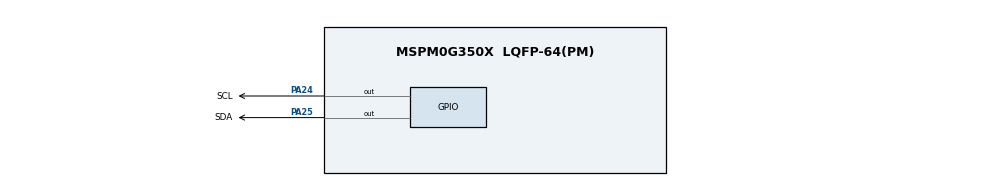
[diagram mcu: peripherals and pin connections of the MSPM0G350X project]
/**
 * These arguments were used when this file was generated. They will be automatically applied on subsequent loads
 * via the GUI or CLI. Run CLI with '--help' for additional information on how to override these arguments.
 * @cliArgs --device "MSPM0G350X" --package "LQFP-64(PM)" --part "Default" --product "mspm0_sdk@2.01.00.03"
 * @versions {"tool":"1.20.0+3587"}
 */

/**
 * Import the modules used in this configuration.
 */
const GPIO    = scripting.addModule("/ti/driverlib/GPIO", {}, false);
const GPIO1   = GPIO.addInstance();
const SYSCTL  = scripting.addModule("/ti/driverlib/SYSCTL");
const SYSTICK = scripting.addModule("/ti/driverlib/SYSTICK");

/**
 * Write custom configuration values to the imported modules.
 */
GPIO1.$name                         = "OLED";
GPIO1.port                          = "PORTA";
GPIO1.associatedPins.create(2);
GPIO1.associatedPins[0].$name       = "SCL";
GPIO1.associatedPins[0].assignedPin = "24";
GPIO1.associatedPins[0].pin.$assign = "PA24";
GPIO1.associatedPins[1].$name       = "SDA";
GPIO1.associatedPins[1].assignedPin = "25";
GPIO1.associatedPins[1].pin.$assign = "PA25";

const Board = scripting.addModule("/ti/driverlib/Board", {}, false);

SYSCTL.forceDefaultClkConfig = true;

SYSTICK.periodEnable      = true;
SYSTICK.period            = 32000;
SYSTICK.interruptEnable   = true;
SYSTICK.interruptPriority = "0";
SYSTICK.systickEnable     = true;

/**
 * Pinmux solution for unlocked pins/peripherals. This ensures that minor changes to the automatic solver in a future
 * version of the tool will not impact the pinmux you originally saw.  These lines can be completely deleted in order to
 * re-solve from scratch.
 */
Board.peripheral.$suggestSolution          = "DEBUGSS";
Board.peripheral.swclkPin.$suggestSolution = "PA20";
Board.peripheral.swdioPin.$suggestSolution = "PA19";
SYSCTL.peripheral.$suggestSolution         = "SYSCTL";
